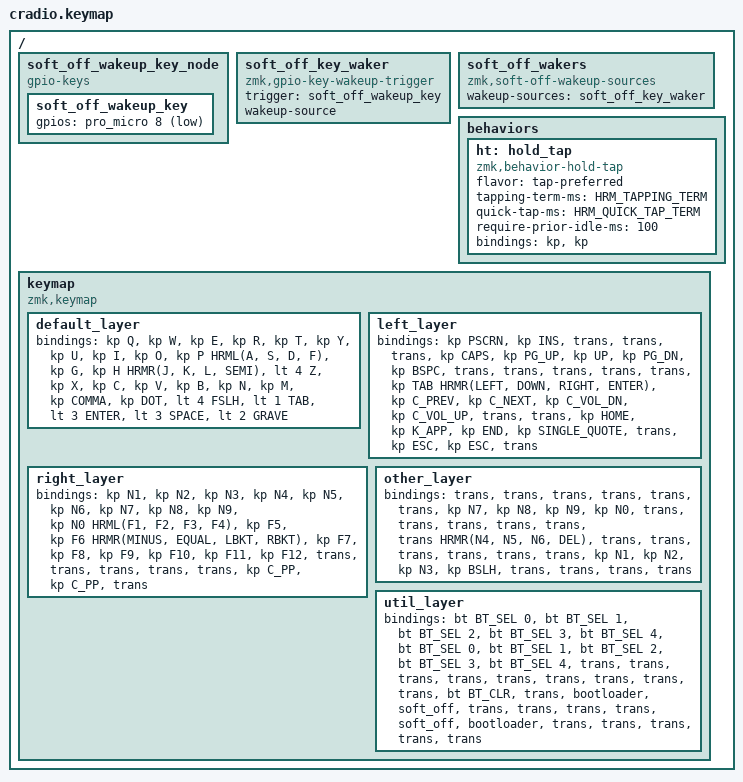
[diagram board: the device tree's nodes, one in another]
// Copyright (c) 2022 The ZMK Contributors
// SPDX-License-Identifier: MIT

#include <behaviors.dtsi>
#include <dt-bindings/zmk/keys.h>
#include <dt-bindings/zmk/bt.h>
#include <dt-bindings/zmk/outputs.h>

#define HRM_TAPPING_TERM 250
#define HRM_QUICK_TAP_TERM 250

// Home row mods macro
#define HRML(k1,k2,k3,k4) &ht LSHFT k1 &ht LCTRL k2 &ht LGUI k3 &ht LALT k4
#define HRMR(k1,k2,k3,k4) &ht LALT k1 &ht LGUI k2 &ht LCTRL k3 &ht RSHFT k4

/ {
    soft_off_wakeup_key_node {
        compatible = "gpio-keys";
        soft_off_wakeup_key: soft_off_wakeup_key {
            gpios = <&pro_micro 8 (GPIO_ACTIVE_LOW | GPIO_PULL_UP)>;
        };
    };

    soft_off_key_waker: soft_off_key_waker {
        compatible = "zmk,gpio-key-wakeup-trigger";
        trigger = <&soft_off_wakeup_key>;
        wakeup-source;
    };

    soft_off_wakers {
        compatible = "zmk,soft-off-wakeup-sources";
        wakeup-sources = <&soft_off_key_waker>;
    };

    behaviors {
        ht: hold_tap {
            compatible = "zmk,behavior-hold-tap";
            #binding-cells = <2>;
            flavor = "tap-preferred";
            tapping-term-ms = <HRM_TAPPING_TERM>;
            quick-tap-ms = <HRM_QUICK_TAP_TERM>;
            require-prior-idle-ms = <100>;
            bindings = <&kp>, <&kp>;
        };
    };

    keymap {
        compatible = "zmk,keymap";
        default_layer {
            bindings = <
        //╭──────────┬──────────┬──────────┬──────────┬──────────╮   ╭──────────┬──────────┬──────────┬──────────┬──────────╮
        //│  Q       │  W       │  E       │  R       │  T       │   │  Y       │  U       │  I       │  O       │  P       │
            &kp Q      &kp W      &kp E      &kp R      &kp T          &kp Y      &kp U      &kp I      &kp O      &kp P
        //├──────────┼──────────┼──────────┼──────────┼──────────┤   ├──────────┼──────────┼──────────┼──────────┼──────────┤
        //│  A       │  S       │  D       │  F       │  G       │   │  H       │  J       │  K       │  L       │ ;        │
            HRML(A,        S,         D,         F)     &kp G          &kp H      HRMR(J,        K,         L,        SEMI)
        //├──────────┼──────────┼──────────┼──────────┼──────────┤   ├──────────┼──────────┼──────────┼──────────┼──────────┤
        //│  Z       │  X       │  C       │  V       │  B       │   │  N       │  M       │ , <      │ . >      │ / ?      │
            &lt 4 Z      &kp X      &kp C      &kp V      &kp B          &kp N      &kp M      &kp COMMA  &kp DOT    &lt 4 FSLH
        //╰──────────┴──────────┴──────────┼──────────┼──────────┤   ├──────────┼──────────┼──────────┴──────────┴──────────╯
                                            &lt 1 TAB   &lt 3 ENTER     &lt 3 SPACE  &lt 2 GRAVE
        //                                 ╰──────────┴──────────╯   ╰──────────┴──────────╯
            >;
        };

        left_layer {
            bindings = <
            &kp PSCRN &kp INS &trans &trans &trans &kp CAPS &kp PG_UP &kp UP &kp PG_DN &kp BSPC
            &trans &trans &trans &trans &trans &kp TAB HRMR(LEFT, DOWN, RIGHT, ENTER)
            &kp C_PREV &kp C_NEXT &kp C_VOL_DN &kp C_VOL_UP &trans &trans &kp HOME &kp K_APP &kp END &kp SINGLE_QUOTE
            &trans &kp ESC &kp ESC &trans
            >;
        };

        right_layer {
            bindings = <
            &kp N1 &kp N2 &kp N3 &kp N4 &kp N5 &kp N6 &kp N7 &kp N8 &kp N9 &kp N0
            HRML(F1, F2, F3, F4) &kp F5 &kp F6 HRMR(MINUS, EQUAL, LBKT, RBKT)
            &kp F7 &kp F8 &kp F9 &kp F10 &kp F11 &kp F12 &trans &trans &trans &trans
            &trans &kp C_PP &kp C_PP &trans
            >;
        };

        other_layer {
            bindings = <
            &trans &trans &trans &trans &trans &trans &kp N7 &kp N8 &kp N9 &kp N0
            &trans &trans &trans &trans &trans &trans HRMR(N4, N5, N6, DEL)
            &trans &trans &trans &trans &trans &trans &kp N1 &kp N2 &kp N3 &kp BSLH
            &trans &trans &trans &trans
            >;
        };

        util_layer {
            bindings = <
            &bt BT_SEL 0 &bt BT_SEL 1 &bt BT_SEL 2 &bt BT_SEL 3 &bt BT_SEL 4 &bt BT_SEL 0 &bt BT_SEL 1 &bt BT_SEL 2 &bt BT_SEL 3 &bt BT_SEL 4
            &trans &trans &trans &trans &trans &trans &trans &trans &trans &bt BT_CLR
            &trans &bootloader &soft_off &trans &trans &trans &trans &soft_off &bootloader &trans
            &trans &trans &trans &trans
            >;
        };

        // right_layer {
        //     bindings = <
        // //╭──────────┬──────────┬──────────┬──────────┬──────────╮   ╭──────────┬──────────┬──────────┬──────────┬──────────╮
        // //│ INSERT   │  1       │  2       │  3       │          │   │ HOME     │ PAGE DN  │ PAGE UP  │ END      │  :       │
        //     &kp INS    &kp N1     &kp N2     &kp N3     &trans         &kp HOME   &kp PG_DN  &kp PG_UP  &kp END    &kp COLON
        // //├──────────┼──────────┼──────────┼──────────┼──────────┤   ├──────────┼──────────┼──────────┼──────────┼──────────┤
        // //│ DELETE   │  4       │  5       │  6       │          │   │ LEFT     │ DOWN     │ UP       │ RIGHT    │  ;       │
        //     &kp DEL    &kp N4     &kp N5     &kp N6     &trans         &kp LEFT   &kp DOWN   &kp UP   &kp RIGHT   &kp SEMI
        // //├──────────┼──────────┼──────────┼──────────┼──────────┤   ├──────────┼──────────┼──────────┼──────────┼──────────┤
        // //│ CAPS     │  7       │  8       │  9       │  0       │   │          │          │          │          │          │
        //    &caps_word  &kp N7     &kp N8     &kp N9     &kp N0         &trans     &trans     &trans     &trans     &trans
        // //╰──────────┴──────────┴──────────┼──────────┼──────────┤   ├──────────┼──────────┼──────────┴──────────┴──────────╯
        //                                      &trans     &kp ESC        &trans     &trans
        // //                                 ╰──────────┴──────────╯   ╰──────────┴──────────╯
        //     >;
        // };

        // left_layer {
        //     bindings = <
        // //╭──────────┬──────────┬──────────┬──────────┬──────────╮   ╭──────────┬──────────┬──────────┬──────────┬──────────╮
        // //│          │  [       │  {       │  }       │          │   │  ^       │  (       │  )       │  ]       │  ~       │
        //     &trans     &kp LBKT   &kp LBRC   &kp RBRC   &trans         &kp CARET  &kp LPAR   &kp RPAR   &kp RBKT   &kp TILDE
        // //├──────────┼──────────┼──────────┼──────────┼──────────┤   ├──────────┼──────────┼──────────┼──────────┼──────────┤
        // //│  !       │  @       │  #       │  $       │  %       │   │  *       │  -       │  =       │  \       │  `       │
        //     &kp EXCL   &kp AT     &kp HASH   &kp DLLR   &kp PRCNT      &kp ASTRK  &kp MINUS  &kp EQUAL  &kp BSLH   &kp GRAVE
        // //├──────────┼──────────┼──────────┼──────────┼──────────┤   ├──────────┼──────────┼──────────┼──────────┼──────────┤
        // //│          │          │          │          │          │   │  &       │  _       │  +       │  │       │          │
        //     &trans     &trans     &trans     &trans     &trans         &kp AMPS   &kp UNDER  &kp PLUS   &kp PIPE   &trans
        // //╰──────────┴──────────┴──────────┼──────────┼──────────┤   ├──────────┼──────────┼──────────┴──────────┴──────────╯
        //                                      &trans     &trans         &trans     &trans
        // //                                 ╰──────────┴──────────╯   ╰──────────┴──────────╯
        //     >;
        // };

        // tri_layer {
        //     bindings = <
        // //╭──────────┬──────────┬──────────┬──────────┬──────────╮   ╭──────────┬──────────┬──────────┬──────────┬──────────╮
        // //│ RESET    │          │          │          │PROFILE 0 │   │          │          │          │          │  RESET   │
        //    &sys_reset  &trans     &trans     &trans    &bt BT_SEL 0    &trans     &trans     &trans     &trans    &sys_reset
        // //├──────────┼──────────┼──────────┼──────────┼──────────┤   ├──────────┼──────────┼──────────┼──────────┼──────────┤
        // //│BOOTLOADER│          │          │          │PROFILE 1 │   │          │          │          │          │BOOTLOADER│
        //   &bootloader  &trans     &trans     &trans    &bt BT_SEL 1    &trans     &trans     &trans     &trans    &bootloader
        // //├──────────┼──────────┼──────────┼──────────┼──────────┤   ├──────────┼──────────┼──────────┼──────────┼──────────┤
        // //│          │          │          │ CLEAR BT │PROFILE 2 │   │          │          │          │          │          │
        //     &trans     &trans     &trans    &bt BT_CLR &bt BT_SEL 2    &trans     &trans     &trans     &trans     &trans
        // //╰──────────┴──────────┴──────────┼──────────┼──────────┤   ├──────────┼──────────┼──────────┴──────────┴──────────╯
        //                                      &trans     &trans         &trans     &trans
        // //                                 ╰──────────┴──────────╯   ╰──────────┴──────────╯
        //     >;
        // };
    };
};
